# PT32x066xx register map
File version: 0.3
Registers are 32-bit, read-write, reset 0x0 unless marked. A register's access mark holds for its fields unless they carry their own. Offsets are from the block's base; [hi:lo] are bit positions; {n}, {i} and the like mark numbered series.

## RCC — Reset and clock control
Base 0x40020000
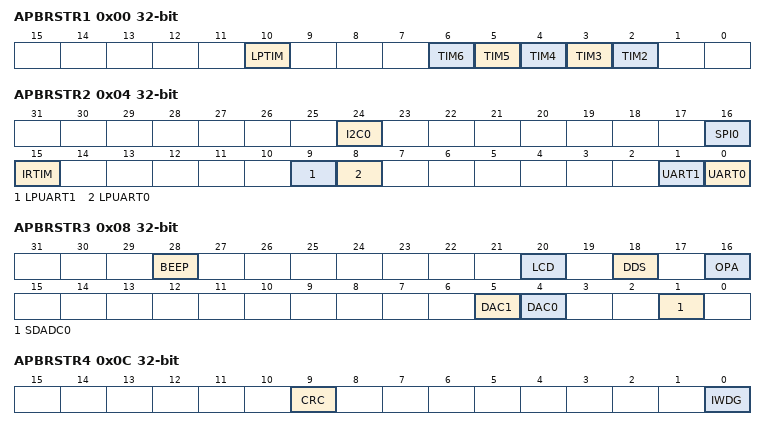
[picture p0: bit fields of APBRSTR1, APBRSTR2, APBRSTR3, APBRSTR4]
0x00 APBRSTR1 — APB Peripheral Reset Register 1
  [10] LPTIM — LPTIM reset
  [n] TIM{n} (n=2..6) — TIM{n} reset
0x04 APBRSTR2 — APB Peripheral Reset Register 2
  [24] I2C0 — I2C0 reset
  [16] SPI0 — SPI0 reset
  [15] IRTIM — IRTIM reset
  [9] LPUART1 — LPUART1 reset
  [8] LPUART0 — LPUART0 reset
  [1] UART1 — UART1 reset
  [0] UART0 — UART0 reset
0x08 APBRSTR3 — APB Peripheral Reset Register 3
  [28] BEEP — BEEP reset
  [20] LCD — LCD reset
  [18] DDS — DDS reset
  [16] OPA — OPA reset
  [5] DAC1 — DAC1 reset
  [4] DAC0 — DAC0 reset
  [1] SDADC0 — SDADC0 reset
0x0C APBRSTR4 — APB Peripheral Reset Register 4
  [9] CRC — CRC reset
  [0] IWDG — IWDG reset
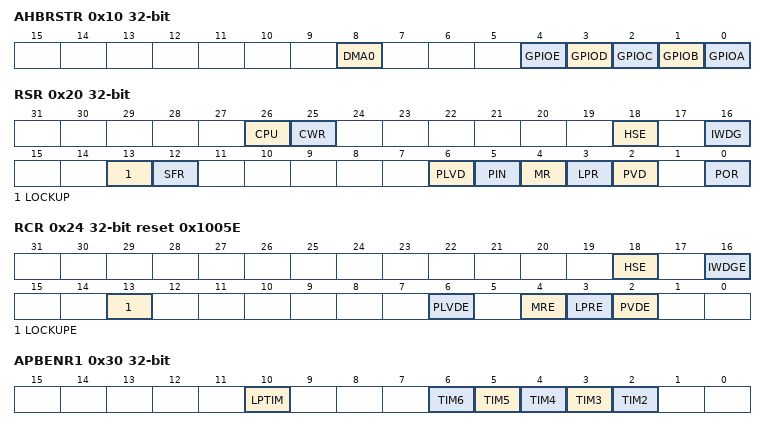
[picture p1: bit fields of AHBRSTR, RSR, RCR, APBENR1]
0x10 AHBRSTR — AHB Peripheral Reset Register
  [8] DMA0 — DMA0 reset
  [4] GPIOE — GPIOE reset
  [3] GPIOD — GPIOD reset
  [2] GPIOC — GPIOC reset
  [1] GPIOB — GPIOB reset
  [0] GPIOA — GPIOA reset
0x20 RSR — Reset Status Register
  [26] CPU — CPU core reset flag
  [25] CWR — Configuration word reset flag
  [18] HSE — HSE fail reset flag
  [16] IWDG — IWDG reset flag
  [13] LOCKUP — LOCKUP reset flag
  [12] SFR — Software reset flag
  [6] PLVD — Power low voltage detection reset flag
  [5] PIN — Pin reset flag
  [4] MR — MR low voltage detection reset flag
  [3] LPR — LPR low voltage detection reset flag
  [2] PVD — PVD reset flag
  [0] POR — Power reset flag
0x24 RCR reset 0x1005E — Reset Control Register
  [18] HSE — HSE reset enable
  [16] IWDGE — IWDG reset enable
  [13] LOCKUPE — LOCKUP reset enable
  [6] PLVDE — Power low voltage detection reset enable
  [4] MRE — MR low voltage detection reset enable
  [3] LPRE — LPR low voltage detection reset enable
  [2] PVDE — PVD reset enable
0x28 ASRCR wo — Advanced Software Reset Control Register
  [15:0] KEY
0x30 APBENR1 — APB Peripheral Clock Enable Register 1
  [10] LPTIM — LPTIM clock enable
  [n] TIM{n} (n=2..6) — TIM{n} clock enable
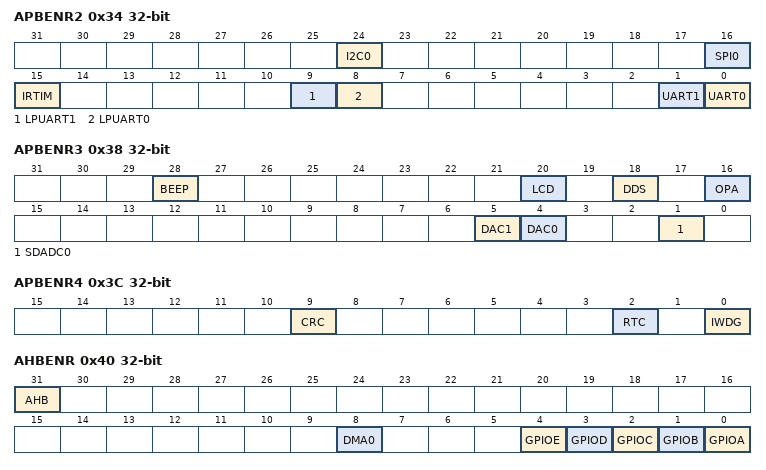
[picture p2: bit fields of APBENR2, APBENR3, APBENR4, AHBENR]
0x34 APBENR2 — APB Peripheral Clock Enable Register 2
  [24] I2C0 — I2C0 clock enable
  [16] SPI0 — SPI0 clock enable
  [15] IRTIM — IRTIM clock enable
  [9] LPUART1 — LPUART1 clock enable
  [8] LPUART0 — LPUART0 clock enable
  [1] UART1 — UART1 clock enable
  [0] UART0 — UART0 clock enable
0x38 APBENR3 — APB Peripheral Clock Enable Register 3
  [28] BEEP — BEEP clock enable
  [20] LCD — LCD clock enable
  [18] DDS — DDS clock enable
  [16] OPA — OPA clock enable
  [5] DAC1 — DAC1 clock enable
  [4] DAC0 — DAC0 clock enable
  [1] SDADC0 — SDADC0 clock enable
0x3C APBENR4 — APB Peripheral Clock Enable Register 4
  [9] CRC — CRC clock enable
  [2] RTC — RTC clock enable
  [0] IWDG — IWDG clock enable
0x40 AHBENR — AHB Peripheral Clock Enable Register
  [31] AHB — AHB clock enable
  [8] DMA0 — DMA0 clock enable
  [4] GPIOE — GPIOE clock enable
  [3] GPIOD — GPIOD clock enable
  [2] GPIOC — GPIOC clock enable
  [1] GPIOB — GPIOB clock enable
  [0] GPIOA — GPIOA clock enable
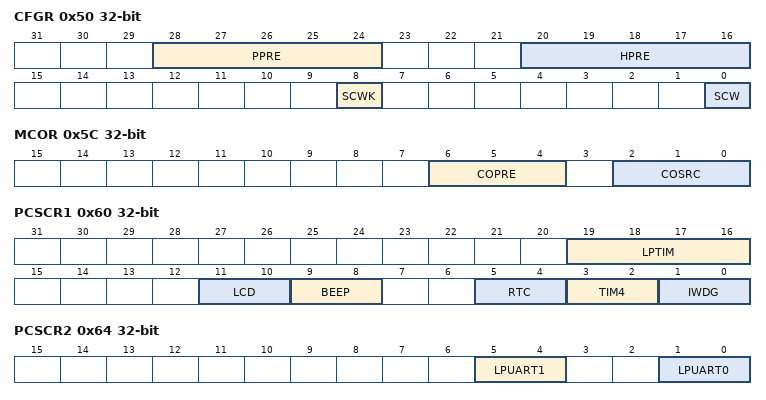
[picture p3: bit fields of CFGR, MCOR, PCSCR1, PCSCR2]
0x50 CFGR — Clock Configuration Register
  [28:24] PPRE — PCLK prescaler
  [20:16] HPRE — HCLK prescaler
  [8] SCWK — System clock after wakeup
  [0] SCW — System clock switch
0x5C MCOR — MCO Control Register
  [6:4] COPRE — Clock output prescaler
  [2:0] COSRC — Clock output source
0x60 PCSCR1 — Peripheral Clock Source Configuration Register 1
  [19:16] LPTIM — LPTIM clock source selection
  [11:10] LCD — LCD clock source selection
  [9:8] BEEP — BEEP clock source selection
  [5:4] RTC — RTC clock source selection
  [3:2] TIM4 — TIM4 clock source selection
  [1:0] IWDG — IWDG clock source selection
0x64 PCSCR2 — Peripheral Clock Source Configuration Register 2
  [5:4] LPUART1 — LPUART1 clock source selection
  [1:0] LPUART0 — LPUART0 clock source selection
0x70 HSICR reset 0x1 — HSI Control Register
  [0] EN — HSI enable
0x74 LSICR reset 0x1 — LSI Control Register
  [0] EN — LSI enable
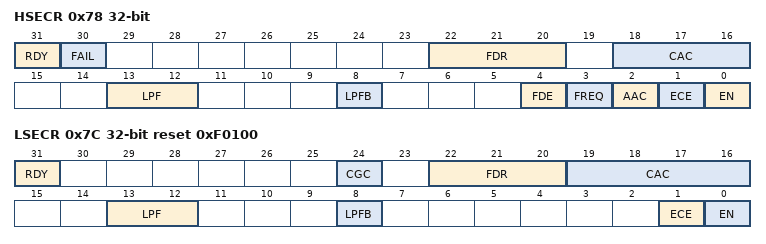
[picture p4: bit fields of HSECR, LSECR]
0x78 HSECR — HSE Control Register
  [31] RDY — HSE ready flag
  [30] FAIL — HSE failure flag
  [22:20] FDR — Feedback resistance selection
  [18:16] CAC — Current adjustment control
  [13:12] LPF — Low pass filter
  [8] LPFB — Low pass filter bypass enable
  [4] FDE — HSE fail detecting enable
  [3] FREQ — HSE frequency range
  [2] AAC — Automatic amplitude control
  [1] ECE — External clock enable
  [0] EN — HSE enable
0x7C LSECR access per field reset 0xF0100 — LSE Control Register
  [31] RDY ro — LSE ready flag
  [24] CGC rw — Current gear control
  [22:20] FDR rw — Feedback resistance selection
  [19:16] CAC rw — Current adjustment control
  [13:12] LPF rw — Low pass filter
  [8] LPFB rw — Low pass filter bypass enable
  [1] ECE rw — External clock enable
  [0] EN rw — LSE enable
